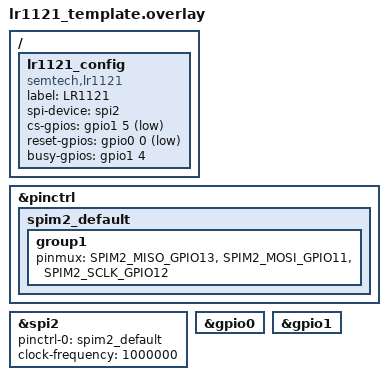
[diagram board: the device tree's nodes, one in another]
/**
 * @file lr1121_template.overlay
 * @brief LR1121 LoRa Transceiver Device Tree Template
 * 
 * This template shows how to add LR1121 LoRa/GFSK transceiver support
 * to any Zephyr board using device tree overlay.
 * 
 * USAGE:
 * 1. Copy this template to your board overlay file (e.g., myboard.overlay)
 * 2. Modify SPI bus, GPIO pins, and pinmux according to your hardware
 * 3. Enable required configs in your board.conf:
 *    CONFIG_AKIRA_MODULE_RF=y
 *    CONFIG_AKIRA_RF_FRAMEWORK=y
 *    CONFIG_AKIRA_LR1121=y
 *    CONFIG_AKIRA_WASM_RF=y
 * 4. Build with your board target
 */

// Include required headers
#include <zephyr/dt-bindings/gpio/gpio.h>
#include <zephyr/dt-bindings/spi/spi.h>

// ============================================================================
// STEP 1: Configure SPI Bus for LR1121
// ============================================================================
// The LR1121 requires a dedicated SPI bus. Choose an available SPI peripheral
// on your board (e.g., spi1, spi2, spi3).

// EXAMPLE: Configure pinmux for SPI2 (adjust pin numbers for your board)
&pinctrl
{
    // Create a pinmux configuration for your SPI bus
    spim2_default: spim2_default {
        group1 {
            // Modify these pin numbers to match your board's SPI connections
            pinmux = <SPIM2_MISO_GPIO13>,  // MISO (Master In, Slave Out)
                     <SPIM2_MOSI_GPIO11>,  // MOSI (Master Out, Slave In)
                     <SPIM2_SCLK_GPIO12>;  // SCK  (Clock)
        };
    };
};

// Enable and configure the SPI peripheral
&spi2  // Change to spi1, spi3, etc. based on your board
{
    status = "okay";
    pinctrl-0 = <&spim2_default>;
    pinctrl-names = "default";
    clock-frequency = <1000000>;  // Start at 1 MHz (can increase to 10 MHz)
    
    // IMPORTANT: Do NOT add cs-gpios here - LR1121 requires manual NSS control
    // The driver will control CS pin directly via GPIO
};

// ============================================================================
// STEP 2: Enable Required GPIO Controllers
// ============================================================================
// Ensure the GPIO controllers for your chosen pins are enabled

&gpio0
{
    status = "okay";
};

&gpio1
{
    status = "okay";
};

// Add more GPIO controllers as needed (&gpio2, &gpio3, etc.)

// ============================================================================
// STEP 3: Add LR1121 Device Node
// ============================================================================
/ {
    // Create the LR1121 configuration node
    lr1121_config {
        compatible = "semtech,lr1121";
        status = "okay";
        label = "LR1121";
        
        // Reference to the SPI bus (must match the SPI node above)
        spi-device = <&spi2>;
        
        // GPIO Pin Assignments (modify these for your board)
        // Format: <&gpio_controller pin_number flags>
        
        // NSS (Chip Select) - Must be manually controlled
        // Choose any available GPIO pin, configure as active-low output
        cs-gpios = <&gpio1 5 GPIO_ACTIVE_LOW>;
        
        // RESET - Used to reset the LR1121 chip
        // Choose any available GPIO pin, configure as active-low output
        reset-gpios = <&gpio0 0 GPIO_ACTIVE_LOW>;
        
        // BUSY - LR1121 busy indicator (input)
        // Choose any available GPIO pin, configure as input with pull-down
        busy-gpios = <&gpio1 4 (GPIO_ACTIVE_HIGH | GPIO_PULL_DOWN)>;
        
        // IRQ (Optional) - Interrupt request from LR1121
        // Uncomment and configure if you want to use interrupt-driven mode
        // irq-gpios = <&gpio1 3 GPIO_ACTIVE_HIGH>;
    };
};

// ============================================================================
// HARDWARE CONNECTION GUIDE
// ============================================================================
// 
// LR1121 Pin    Signal    Board Connection      Device Tree Config
// -----------  ---------  -------------------   ---------------------
// Pin 1        NSS        GPIO (any available)  cs-gpios
// Pin 2        SCK        SPI SCK               spim*_default pinmux
// Pin 3        MISO       SPI MISO              spim*_default pinmux
// Pin 4        MOSI       SPI MOSI              spim*_default pinmux
// Pin 5        BUSY       GPIO (input)          busy-gpios
// Pin 6        RESET      GPIO (any available)  reset-gpios
// Pin 7        IRQ        GPIO (optional)       irq-gpios (uncomment)
// Pin 8        VDD        3.3V power            N/A
// Pin 9        GND        Ground                N/A
//
// NOTES:
// - LR1121 operates at 3.3V logic levels
// - Ensure SPI frequency is between 1-10 MHz
// - NSS requires manual control (no hardware CS)
// - BUSY must be monitored before/after SPI transactions
// - RESET is active-low (pulse low to reset)
// - IRQ is optional but recommended for RX interrupt mode
//
// ============================================================================
// PIN SELECTION TIPS
// ============================================================================
//
// 1. SPI Pins: Check your board schematic for dedicated SPI pins.
//    Most SoCs have multiple SPI peripherals (SPI0, SPI1, SPI2, etc.)
//
// 2. GPIO Pins: Choose GPIOs that are:
//    - Not used by other peripherals (check your board schematic)
//    - Accessible on your board's headers
//    - Not reserved for special functions (e.g., flash, RAM)
//
// 3. Interrupt Pin (IRQ): If using interrupts, choose a GPIO that:
//    - Supports external interrupts
//    - Has low latency (not shared with other high-priority interrupts)
//
// 4. Example ESP32-S3 pin mapping:
//    GPIO37 → NSS (CS)
//    GPIO36 → BUSY
//    GPIO0  → RESET
//    GPIO11 → MOSI
//    GPIO12 → SCK
//    GPIO13 → MISO
//    (GPIO35 → IRQ, optional)
//
// 5. Example nRF52840 pin mapping:
//    P0.03 → NSS (CS)
//    P0.04 → BUSY
//    P0.05 → RESET
//    P0.06 → MOSI
//    P0.07 → SCK
//    P0.08 → MISO
//
// ============================================================================
// TESTING YOUR CONFIGURATION
// ============================================================================
//
// After building and flashing, use these shell commands to test:
//
//   uart:~$ rf status           # Check if RF module is enabled
//   uart:~$ rf init 3           # Initialize LR1121 (chip=3)
//   uart:~$ rf freq 868000000   # Set frequency to 868 MHz
//   uart:~$ rf power 14         # Set TX power to 14 dBm
//   uart:~$ rf rssi             # Read RSSI value
//   uart:~$ rf send "Hello"     # Send test message
//   uart:~$ rf recv 5000        # Receive (5 second timeout)
//   uart:~$ rf deinit           # Shutdown RF
//
// Expected output on successful init:
//   [00:00:05.123,456] <inf> akira_lr1121: Resetting LR1121...
//   [00:00:05.234,567] <inf> akira_lr1121: LR1121 version: HW=0x21, FW=3.1
//   [00:00:05.345,678] <inf> akira_lr1121: LR1121 initialized successfully
//   [00:00:05.456,789] <inf> akira_rf_api: RF driver 'LR1121' initialized
//
// ============================================================================
// TROUBLESHOOTING
// ============================================================================
//
// Problem: "SPI device not ready"
// Solution: Check that SPI controller is enabled in device tree and pinmux
//           is correct for your board.
//
// Problem: "CS GPIO not ready" / "RESET GPIO not ready" / "BUSY GPIO not ready"
// Solution: Verify GPIO controllers are enabled (&gpio0, &gpio1, etc.) and
//           pin numbers are correct for your board.
//
// Problem: "BUSY timeout"
// Solution: Check BUSY pin wiring, ensure pull-down resistor is present,
//           verify GPIO pin number is correct.
//
// Problem: "Failed to read version"
// Solution: Check all SPI wiring (MOSI, MISO, SCK, NSS), ensure LR1121 has
//           power and ground connected, verify SPI frequency is valid (1-10 MHz).
//
// Problem: "Driver not found for chip type 3"
// Solution: Ensure CONFIG_AKIRA_LR1121=y is set in your board.conf file.
//
// ============================================================================

